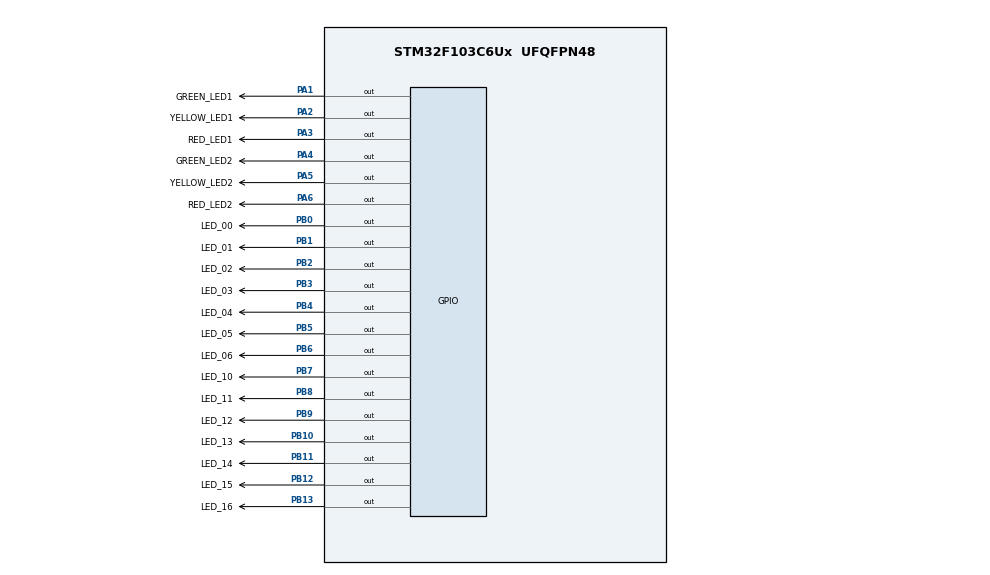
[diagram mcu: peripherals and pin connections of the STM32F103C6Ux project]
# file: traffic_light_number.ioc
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Mcu.Family=STM32F1
Mcu.Name=STM32F103C6Ux
Mcu.Package=UFQFPN48
NVIC.PriorityGroup=NVIC_PRIORITYGROUP_4
NVIC.TIM2_IRQn=true\:0\:0\:false\:false\:true\:true\:true
PA1.GPIO_Label=GREEN_LED1
PA1.Signal=GPIO_Output
PA2.GPIO_Label=YELLOW_LED1
PA2.Signal=GPIO_Output
PA3.GPIO_Label=RED_LED1
PA3.Signal=GPIO_Output
PA4.GPIO_Label=GREEN_LED2
PA4.Signal=GPIO_Output
PA5.GPIO_Label=YELLOW_LED2
PA5.Signal=GPIO_Output
PA6.GPIO_Label=RED_LED2
PA6.Signal=GPIO_Output
PB0.GPIO_Label=LED_00
PB0.Signal=GPIO_Output
PB1.GPIO_Label=LED_01
PB1.Signal=GPIO_Output
PB10.GPIO_Label=LED_13
PB10.Signal=GPIO_Output
PB11.GPIO_Label=LED_14
PB11.Signal=GPIO_Output
PB12.GPIO_Label=LED_15
PB12.Signal=GPIO_Output
PB13.GPIO_Label=LED_16
PB13.Signal=GPIO_Output
PB2.GPIO_Label=LED_02
PB2.Signal=GPIO_Output
PB3.GPIO_Label=LED_03
PB3.Signal=GPIO_Output
PB4.GPIO_Label=LED_04
PB4.Signal=GPIO_Output
PB5.GPIO_Label=LED_05
PB5.Signal=GPIO_Output
PB6.GPIO_Label=LED_06
PB6.Signal=GPIO_Output
PB7.GPIO_Label=LED_10
PB7.Signal=GPIO_Output
PB8.GPIO_Label=LED_11
PB8.Signal=GPIO_Output
PB9.GPIO_Label=LED_12
PB9.Signal=GPIO_Output
ProjectManager.HeapSize=0x200
ProjectManager.StackSize=0x400
ProjectManager.TargetToolchain=STM32CubeIDE
RCC.APB1Freq_Value=8000000
RCC.APB2Freq_Value=8000000
TIM2.Period=9
TIM2.Prescaler=7999
VP_SYS_VS_ND.Mode=No_Debug
VP_TIM2_VS_ClockSourceINT.Mode=Internal
board=custom

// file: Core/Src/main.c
/* USER CODE BEGIN Header */
/**
  ******************************************************************************
  * @file           : main.c
  * @brief          : Main program body
  ******************************************************************************
  * @attention
  *
  * <h2><center>&copy; Copyright (c) 2024 STMicroelectronics.
  * All rights reserved.</center></h2>
  *
  * This software component is licensed by ST under BSD 3-Clause license,
  * the "License"; You may not use this file except in compliance with the
  * License. You may obtain a copy of the License at:
  *                        opensource.org/licenses/BSD-3-Clause
  *
  ******************************************************************************
  */
/* USER CODE END Header */
#include "main.h"
#include "software_timer.h"

TIM_HandleTypeDef htim2;

void SystemClock_Config(void);
static void MX_GPIO_Init(void);
static void MX_TIM2_Init(void);

void display7SEG_1(int num){
	  switch(num){
	  case 0 :
		  HAL_GPIO_WritePin ( LED_10_GPIO_Port , LED_10_Pin , GPIO_PIN_RESET ) ;
		  HAL_GPIO_WritePin ( LED_11_GPIO_Port , LED_11_Pin , GPIO_PIN_RESET ) ;
		  HAL_GPIO_WritePin ( LED_12_GPIO_Port , LED_12_Pin , GPIO_PIN_RESET ) ;
		  HAL_GPIO_WritePin ( LED_13_GPIO_Port , LED_13_Pin , GPIO_PIN_RESET ) ;
		  HAL_GPIO_WritePin ( LED_14_GPIO_Port , LED_14_Pin , GPIO_PIN_RESET ) ;
		  HAL_GPIO_WritePin ( LED_15_GPIO_Port , LED_15_Pin , GPIO_PIN_RESET ) ;
		  HAL_GPIO_WritePin ( LED_16_GPIO_Port , LED_16_Pin , GPIO_PIN_SET ) ;
		  break;
	  case 1 :
		  HAL_GPIO_WritePin ( LED_10_GPIO_Port , LED_10_Pin , GPIO_PIN_SET ) ;
		  HAL_GPIO_WritePin ( LED_11_GPIO_Port , LED_11_Pin , GPIO_PIN_RESET ) ;
		  HAL_GPIO_WritePin ( LED_12_GPIO_Port , LED_12_Pin , GPIO_PIN_RESET ) ;
		  HAL_GPIO_WritePin ( LED_13_GPIO_Port , LED_13_Pin , GPIO_PIN_SET ) ;
		  HAL_GPIO_WritePin ( LED_14_GPIO_Port , LED_14_Pin , GPIO_PIN_SET ) ;
		  HAL_GPIO_WritePin ( LED_15_GPIO_Port , LED_15_Pin , GPIO_PIN_SET ) ;
		  HAL_GPIO_WritePin ( LED_16_GPIO_Port , LED_16_Pin , GPIO_PIN_SET ) ;
		  break;
	  case 2 :
		  HAL_GPIO_WritePin ( LED_10_GPIO_Port , LED_10_Pin , GPIO_PIN_RESET ) ;
		  HAL_GPIO_WritePin ( LED_11_GPIO_Port , LED_11_Pin , GPIO_PIN_RESET ) ;
		  HAL_GPIO_WritePin ( LED_12_GPIO_Port , LED_12_Pin , GPIO_PIN_SET ) ;
		  HAL_GPIO_WritePin ( LED_13_GPIO_Port , LED_13_Pin , GPIO_PIN_RESET ) ;
		  HAL_GPIO_WritePin ( LED_14_GPIO_Port , LED_14_Pin , GPIO_PIN_RESET ) ;
		  HAL_GPIO_WritePin ( LED_15_GPIO_Port , LED_15_Pin , GPIO_PIN_SET ) ;
		  HAL_GPIO_WritePin ( LED_16_GPIO_Port , LED_16_Pin , GPIO_PIN_RESET ) ;
		  break;
	  case 3 :
		  HAL_GPIO_WritePin ( LED_10_GPIO_Port , LED_10_Pin , GPIO_PIN_RESET ) ;
		  HAL_GPIO_WritePin ( LED_11_GPIO_Port , LED_11_Pin , GPIO_PIN_RESET ) ;
		  HAL_GPIO_WritePin ( LED_12_GPIO_Port , LED_12_Pin , GPIO_PIN_RESET ) ;
		  HAL_GPIO_WritePin ( LED_13_GPIO_Port , LED_13_Pin , GPIO_PIN_RESET ) ;
		  HAL_GPIO_WritePin ( LED_14_GPIO_Port , LED_14_Pin , GPIO_PIN_SET ) ;
		  HAL_GPIO_WritePin ( LED_15_GPIO_Port , LED_15_Pin , GPIO_PIN_SET ) ;
		  HAL_GPIO_WritePin ( LED_16_GPIO_Port , LED_16_Pin , GPIO_PIN_RESET ) ;
		  break;
	  case 4 :
		  HAL_GPIO_WritePin ( LED_10_GPIO_Port , LED_10_Pin , GPIO_PIN_SET ) ;
		  HAL_GPIO_WritePin ( LED_11_GPIO_Port , LED_11_Pin , GPIO_PIN_RESET ) ;
		  HAL_GPIO_WritePin ( LED_12_GPIO_Port , LED_12_Pin , GPIO_PIN_RESET ) ;
		  HAL_GPIO_WritePin ( LED_13_GPIO_Port , LED_13_Pin , GPIO_PIN_SET ) ;
		  HAL_GPIO_WritePin ( LED_14_GPIO_Port , LED_14_Pin , GPIO_PIN_SET ) ;
		  HAL_GPIO_WritePin ( LED_15_GPIO_Port , LED_15_Pin , GPIO_PIN_RESET ) ;
		  HAL_GPIO_WritePin ( LED_16_GPIO_Port , LED_16_Pin , GPIO_PIN_RESET ) ;
		  break;
	  case 5 :
		  HAL_GPIO_WritePin ( LED_10_GPIO_Port , LED_10_Pin , GPIO_PIN_RESET ) ;
		  HAL_GPIO_WritePin ( LED_11_GPIO_Port , LED_11_Pin , GPIO_PIN_SET ) ;
		  HAL_GPIO_WritePin ( LED_12_GPIO_Port , LED_12_Pin , GPIO_PIN_RESET ) ;
		  HAL_GPIO_WritePin ( LED_13_GPIO_Port , LED_13_Pin , GPIO_PIN_RESET ) ;
		  HAL_GPIO_WritePin ( LED_14_GPIO_Port , LED_14_Pin , GPIO_PIN_SET ) ;
		  HAL_GPIO_WritePin ( LED_15_GPIO_Port , LED_15_Pin , GPIO_PIN_RESET ) ;
		  HAL_GPIO_WritePin ( LED_16_GPIO_Port , LED_16_Pin , GPIO_PIN_RESET ) ;
		  break;
	  case 6 :
		  HAL_GPIO_WritePin ( LED_10_GPIO_Port , LED_10_Pin , GPIO_PIN_RESET ) ;
		  HAL_GPIO_WritePin ( LED_11_GPIO_Port , LED_11_Pin , GPIO_PIN_SET ) ;
		  HAL_GPIO_WritePin ( LED_12_GPIO_Port , LED_12_Pin , GPIO_PIN_RESET ) ;
		  HAL_GPIO_WritePin ( LED_13_GPIO_Port , LED_13_Pin , GPIO_PIN_RESET ) ;
		  HAL_GPIO_WritePin ( LED_14_GPIO_Port , LED_14_Pin , GPIO_PIN_RESET ) ;
		  HAL_GPIO_WritePin ( LED_15_GPIO_Port , LED_15_Pin , GPIO_PIN_RESET ) ;
		  HAL_GPIO_WritePin ( LED_16_GPIO_Port , LED_16_Pin , GPIO_PIN_RESET ) ;
		  break;
	  case 7 :
		  HAL_GPIO_WritePin ( LED_10_GPIO_Port , LED_10_Pin , GPIO_PIN_RESET ) ;
		  HAL_GPIO_WritePin ( LED_11_GPIO_Port , LED_11_Pin , GPIO_PIN_RESET ) ;
		  HAL_GPIO_WritePin ( LED_12_GPIO_Port , LED_12_Pin , GPIO_PIN_RESET ) ;
		  HAL_GPIO_WritePin ( LED_13_GPIO_Port , LED_13_Pin , GPIO_PIN_SET ) ;
		  HAL_GPIO_WritePin ( LED_14_GPIO_Port , LED_14_Pin , GPIO_PIN_SET ) ;
		  HAL_GPIO_WritePin ( LED_15_GPIO_Port , LED_15_Pin , GPIO_PIN_SET ) ;
		  HAL_GPIO_WritePin ( LED_16_GPIO_Port , LED_16_Pin , GPIO_PIN_SET ) ;
		  break;

	  case 8 :
		  HAL_GPIO_WritePin ( LED_10_GPIO_Port , LED_10_Pin , GPIO_PIN_RESET ) ;
		  HAL_GPIO_WritePin ( LED_11_GPIO_Port , LED_11_Pin , GPIO_PIN_RESET ) ;
		  HAL_GPIO_WritePin ( LED_12_GPIO_Port , LED_12_Pin , GPIO_PIN_RESET ) ;
		  HAL_GPIO_WritePin ( LED_13_GPIO_Port , LED_13_Pin , GPIO_PIN_RESET ) ;
		  HAL_GPIO_WritePin ( LED_14_GPIO_Port , LED_14_Pin , GPIO_PIN_RESET ) ;
		  HAL_GPIO_WritePin ( LED_15_GPIO_Port , LED_15_Pin , GPIO_PIN_RESET ) ;
		  HAL_GPIO_WritePin ( LED_16_GPIO_Port , LED_16_Pin , GPIO_PIN_RESET ) ;
		  break;

	  case 9 :
		  HAL_GPIO_WritePin ( LED_10_GPIO_Port , LED_10_Pin , GPIO_PIN_RESET ) ;
		  HAL_GPIO_WritePin ( LED_11_GPIO_Port , LED_11_Pin , GPIO_PIN_RESET ) ;
		  HAL_GPIO_WritePin ( LED_12_GPIO_Port , LED_12_Pin , GPIO_PIN_RESET ) ;
		  HAL_GPIO_WritePin ( LED_13_GPIO_Port , LED_13_Pin , GPIO_PIN_RESET ) ;
		  HAL_GPIO_WritePin ( LED_14_GPIO_Port , LED_14_Pin , GPIO_PIN_SET ) ;
		  HAL_GPIO_WritePin ( LED_15_GPIO_Port , LED_15_Pin , GPIO_PIN_RESET ) ;
		  HAL_GPIO_WritePin ( LED_16_GPIO_Port , LED_16_Pin , GPIO_PIN_RESET ) ;
		  break;
	  default :
		  break;
	  }
  }
void display7SEG_0(int num){
	  switch(num){
	  case 0 :
		  HAL_GPIO_WritePin ( LED_00_GPIO_Port , LED_00_Pin , GPIO_PIN_RESET ) ;
		  HAL_GPIO_WritePin ( LED_01_GPIO_Port , LED_01_Pin , GPIO_PIN_RESET ) ;
		  HAL_GPIO_WritePin ( LED_02_GPIO_Port , LED_02_Pin , GPIO_PIN_RESET ) ;
		  HAL_GPIO_WritePin ( LED_03_GPIO_Port , LED_03_Pin , GPIO_PIN_RESET ) ;
		  HAL_GPIO_WritePin ( LED_04_GPIO_Port , LED_04_Pin , GPIO_PIN_RESET ) ;
		  HAL_GPIO_WritePin ( LED_05_GPIO_Port , LED_05_Pin , GPIO_PIN_RESET ) ;
		  HAL_GPIO_WritePin ( LED_06_GPIO_Port , LED_06_Pin , GPIO_PIN_SET ) ;
		  break;
	  case 1 :
		  HAL_GPIO_WritePin ( LED_00_GPIO_Port , LED_00_Pin , GPIO_PIN_SET ) ;
		  HAL_GPIO_WritePin ( LED_01_GPIO_Port , LED_01_Pin , GPIO_PIN_RESET ) ;
		  HAL_GPIO_WritePin ( LED_02_GPIO_Port , LED_02_Pin , GPIO_PIN_RESET ) ;
		  HAL_GPIO_WritePin ( LED_03_GPIO_Port , LED_03_Pin , GPIO_PIN_SET ) ;
		  HAL_GPIO_WritePin ( LED_04_GPIO_Port , LED_04_Pin , GPIO_PIN_SET ) ;
		  HAL_GPIO_WritePin ( LED_05_GPIO_Port , LED_05_Pin , GPIO_PIN_SET ) ;
		  HAL_GPIO_WritePin ( LED_06_GPIO_Port , LED_06_Pin , GPIO_PIN_SET ) ;
		  break;
	  case 2 :
		  HAL_GPIO_WritePin ( LED_00_GPIO_Port , LED_00_Pin , GPIO_PIN_RESET ) ;
		  HAL_GPIO_WritePin ( LED_01_GPIO_Port , LED_01_Pin , GPIO_PIN_RESET ) ;
		  HAL_GPIO_WritePin ( LED_02_GPIO_Port , LED_02_Pin , GPIO_PIN_SET ) ;
		  HAL_GPIO_WritePin ( LED_03_GPIO_Port , LED_03_Pin , GPIO_PIN_RESET ) ;
		  HAL_GPIO_WritePin ( LED_04_GPIO_Port , LED_04_Pin , GPIO_PIN_RESET ) ;
		  HAL_GPIO_WritePin ( LED_05_GPIO_Port , LED_05_Pin , GPIO_PIN_SET ) ;
		  HAL_GPIO_WritePin ( LED_06_GPIO_Port , LED_06_Pin , GPIO_PIN_RESET ) ;
		  break;
	  case 3 :
		  HAL_GPIO_WritePin ( LED_00_GPIO_Port , LED_00_Pin , GPIO_PIN_RESET ) ;
		  HAL_GPIO_WritePin ( LED_01_GPIO_Port , LED_01_Pin , GPIO_PIN_RESET ) ;
		  HAL_GPIO_WritePin ( LED_02_GPIO_Port , LED_02_Pin , GPIO_PIN_RESET ) ;
		  HAL_GPIO_WritePin ( LED_03_GPIO_Port , LED_03_Pin , GPIO_PIN_RESET ) ;
		  HAL_GPIO_WritePin ( LED_04_GPIO_Port , LED_04_Pin , GPIO_PIN_SET ) ;
		  HAL_GPIO_WritePin ( LED_05_GPIO_Port , LED_05_Pin , GPIO_PIN_SET ) ;
		  HAL_GPIO_WritePin ( LED_06_GPIO_Port , LED_06_Pin , GPIO_PIN_RESET ) ;
		  break;
	  case 4 :
		  HAL_GPIO_WritePin ( LED_00_GPIO_Port , LED_00_Pin , GPIO_PIN_SET ) ;
		  HAL_GPIO_WritePin ( LED_01_GPIO_Port , LED_01_Pin , GPIO_PIN_RESET ) ;
		  HAL_GPIO_WritePin ( LED_02_GPIO_Port , LED_02_Pin , GPIO_PIN_RESET ) ;
		  HAL_GPIO_WritePin ( LED_03_GPIO_Port , LED_03_Pin , GPIO_PIN_SET ) ;
		  HAL_GPIO_WritePin ( LED_04_GPIO_Port , LED_04_Pin , GPIO_PIN_SET ) ;
		  HAL_GPIO_WritePin ( LED_05_GPIO_Port , LED_05_Pin , GPIO_PIN_RESET ) ;
		  HAL_GPIO_WritePin ( LED_06_GPIO_Port , LED_06_Pin , GPIO_PIN_RESET ) ;
		  break;
	  case 5 :
		  HAL_GPIO_WritePin ( LED_00_GPIO_Port , LED_00_Pin , GPIO_PIN_RESET ) ;
		  HAL_GPIO_WritePin ( LED_01_GPIO_Port , LED_01_Pin , GPIO_PIN_SET ) ;
		  HAL_GPIO_WritePin ( LED_02_GPIO_Port , LED_02_Pin , GPIO_PIN_RESET ) ;
		  HAL_GPIO_WritePin ( LED_03_GPIO_Port , LED_03_Pin , GPIO_PIN_RESET ) ;
		  HAL_GPIO_WritePin ( LED_04_GPIO_Port , LED_04_Pin , GPIO_PIN_SET ) ;
		  HAL_GPIO_WritePin ( LED_05_GPIO_Port , LED_05_Pin , GPIO_PIN_RESET ) ;
		  HAL_GPIO_WritePin ( LED_06_GPIO_Port , LED_06_Pin , GPIO_PIN_RESET ) ;
		  break;
	  case 6 :
		  HAL_GPIO_WritePin ( LED_00_GPIO_Port , LED_00_Pin , GPIO_PIN_RESET ) ;
		  HAL_GPIO_WritePin ( LED_01_GPIO_Port , LED_01_Pin , GPIO_PIN_SET ) ;
		  HAL_GPIO_WritePin ( LED_02_GPIO_Port , LED_02_Pin , GPIO_PIN_RESET ) ;
		  HAL_GPIO_WritePin ( LED_03_GPIO_Port , LED_03_Pin , GPIO_PIN_RESET ) ;
		  HAL_GPIO_WritePin ( LED_04_GPIO_Port , LED_04_Pin , GPIO_PIN_RESET ) ;
		  HAL_GPIO_WritePin ( LED_05_GPIO_Port , LED_05_Pin , GPIO_PIN_RESET ) ;
		  HAL_GPIO_WritePin ( LED_06_GPIO_Port , LED_06_Pin , GPIO_PIN_RESET ) ;
		  break;
	  case 7 :
		  HAL_GPIO_WritePin ( LED_00_GPIO_Port , LED_00_Pin , GPIO_PIN_RESET ) ;
		  HAL_GPIO_WritePin ( LED_01_GPIO_Port , LED_01_Pin , GPIO_PIN_RESET ) ;
		  HAL_GPIO_WritePin ( LED_02_GPIO_Port , LED_02_Pin , GPIO_PIN_RESET ) ;
		  HAL_GPIO_WritePin ( LED_03_GPIO_Port , LED_03_Pin , GPIO_PIN_SET ) ;
		  HAL_GPIO_WritePin ( LED_04_GPIO_Port , LED_04_Pin , GPIO_PIN_SET ) ;
		  HAL_GPIO_WritePin ( LED_05_GPIO_Port , LED_05_Pin , GPIO_PIN_SET ) ;
		  HAL_GPIO_WritePin ( LED_06_GPIO_Port , LED_06_Pin , GPIO_PIN_SET ) ;
		  break;

	  case 8 :
		  HAL_GPIO_WritePin ( LED_00_GPIO_Port , LED_00_Pin , GPIO_PIN_RESET ) ;
		  HAL_GPIO_WritePin ( LED_01_GPIO_Port , LED_01_Pin , GPIO_PIN_RESET ) ;
		  HAL_GPIO_WritePin ( LED_02_GPIO_Port , LED_02_Pin , GPIO_PIN_RESET ) ;
		  HAL_GPIO_WritePin ( LED_03_GPIO_Port , LED_03_Pin , GPIO_PIN_RESET ) ;
		  HAL_GPIO_WritePin ( LED_04_GPIO_Port , LED_04_Pin , GPIO_PIN_RESET ) ;
		  HAL_GPIO_WritePin ( LED_05_GPIO_Port , LED_05_Pin , GPIO_PIN_RESET ) ;
		  HAL_GPIO_WritePin ( LED_06_GPIO_Port , LED_06_Pin , GPIO_PIN_RESET ) ;
		  break;

	  case 9 :
		  HAL_GPIO_WritePin ( LED_00_GPIO_Port , LED_00_Pin , GPIO_PIN_RESET ) ;
		  HAL_GPIO_WritePin ( LED_01_GPIO_Port , LED_01_Pin , GPIO_PIN_RESET ) ;
		  HAL_GPIO_WritePin ( LED_02_GPIO_Port , LED_02_Pin , GPIO_PIN_RESET ) ;
		  HAL_GPIO_WritePin ( LED_03_GPIO_Port , LED_03_Pin , GPIO_PIN_RESET ) ;
		  HAL_GPIO_WritePin ( LED_04_GPIO_Port , LED_04_Pin , GPIO_PIN_SET ) ;
		  HAL_GPIO_WritePin ( LED_05_GPIO_Port , LED_05_Pin , GPIO_PIN_RESET ) ;
		  HAL_GPIO_WritePin ( LED_06_GPIO_Port , LED_06_Pin , GPIO_PIN_RESET ) ;
		  break;
	  default :
		  break;
	  }
  }
int main(void)
{

  /* MCU Configuration--------------------------------------------------------*/

  /* Reset of all peripherals, Initializes the Flash interface and the Systick. */
  HAL_Init();

  /* Configure the system clock */
  SystemClock_Config();

  /* Initialize all configured peripherals */
  MX_GPIO_Init();
  MX_TIM2_Init();
  /* USER CODE BEGIN 2 */
  HAL_TIM_Base_Start_IT (& htim2 ) ;
  /* USER CODE END 2 */

  /* Infinite loop */
  /* USER CODE BEGIN WHILE */
  setTimer(0,100);
  int counter=0;
  while (1)
  {
    /* USER CODE END WHILE */
	  if(isTimerExpired(0))
		  {setTimer(0,100);
		  counter++;}
	  	if (counter<=5){
	  		display7SEG_0(5-counter);
	  		display7SEG_1(7-counter);
	  		HAL_GPIO_WritePin(GPIOA, GREEN_LED1_Pin|RED_LED2_Pin, GPIO_PIN_SET);
	  		HAL_GPIO_WritePin(GPIOA, YELLOW_LED1_Pin|RED_LED1_Pin|GREEN_LED2_Pin
	                  |YELLOW_LED2_Pin, GPIO_PIN_RESET);
	  	}
	  	if (counter>5 && counter<=7){
	  		display7SEG_0(7-counter);
	  		display7SEG_1(7-counter);
	  		HAL_GPIO_WritePin(GPIOA, YELLOW_LED1_Pin|RED_LED2_Pin, GPIO_PIN_SET);
	  		HAL_GPIO_WritePin(GPIOA, GREEN_LED1_Pin|RED_LED1_Pin|GREEN_LED2_Pin
	                  |YELLOW_LED2_Pin, GPIO_PIN_RESET);
	  	}
	  	if (counter>7 && counter<=12){
	  		display7SEG_0(14-counter);
	  		display7SEG_1(12-counter);
	  		HAL_GPIO_WritePin(GPIOA, RED_LED1_Pin|GREEN_LED2_Pin, GPIO_PIN_SET);
	  		HAL_GPIO_WritePin(GPIOA, GREEN_LED1_Pin|RED_LED2_Pin|YELLOW_LED1_Pin
	                  |YELLOW_LED2_Pin, GPIO_PIN_RESET);
	  	}
	  	if (counter>12 && counter<=14){
	  		display7SEG_0(14-counter);
	  		display7SEG_1(14-counter);
	  		HAL_GPIO_WritePin(GPIOA, RED_LED1_Pin|YELLOW_LED2_Pin, GPIO_PIN_SET);
	  		HAL_GPIO_WritePin(GPIOA, GREEN_LED1_Pin|RED_LED2_Pin|YELLOW_LED1_Pin
	  	             |GREEN_LED2_Pin, GPIO_PIN_RESET);
	  	}
	  	if(counter>=14){
	  		counter=0;
	  	}
  }
}

void SystemClock_Config(void)
{
  RCC_OscInitTypeDef RCC_OscInitStruct = {0};
  RCC_ClkInitTypeDef RCC_ClkInitStruct = {0};

  /** Initializes the RCC Oscillators according to the specified parameters
  * in the RCC_OscInitTypeDef structure.
  */
  RCC_OscInitStruct.OscillatorType = RCC_OSCILLATORTYPE_HSI;
  RCC_OscInitStruct.HSIState = RCC_HSI_ON;
  RCC_OscInitStruct.HSICalibrationValue = RCC_HSICALIBRATION_DEFAULT;
  RCC_OscInitStruct.PLL.PLLState = RCC_PLL_NONE;
  if (HAL_RCC_OscConfig(&RCC_OscInitStruct) != HAL_OK)
  {
    Error_Handler();
  }
  /** Initializes the CPU, AHB and APB buses clocks
  */
  RCC_ClkInitStruct.ClockType = RCC_CLOCKTYPE_HCLK|RCC_CLOCKTYPE_SYSCLK
                              |RCC_CLOCKTYPE_PCLK1|RCC_CLOCKTYPE_PCLK2;
  RCC_ClkInitStruct.SYSCLKSource = RCC_SYSCLKSOURCE_HSI;
  RCC_ClkInitStruct.AHBCLKDivider = RCC_SYSCLK_DIV1;
  RCC_ClkInitStruct.APB1CLKDivider = RCC_HCLK_DIV1;
  RCC_ClkInitStruct.APB2CLKDivider = RCC_HCLK_DIV1;

  if (HAL_RCC_ClockConfig(&RCC_ClkInitStruct, FLASH_LATENCY_0) != HAL_OK)
  {
    Error_Handler();
  }
}

static void MX_TIM2_Init(void)
{

  TIM_ClockConfigTypeDef sClockSourceConfig = {0};
  TIM_MasterConfigTypeDef sMasterConfig = {0};

  htim2.Instance = TIM2;
  htim2.Init.Prescaler = 7999;
  htim2.Init.CounterMode = TIM_COUNTERMODE_UP;
  htim2.Init.Period = 9;
  htim2.Init.ClockDivision = TIM_CLOCKDIVISION_DIV1;
  htim2.Init.AutoReloadPreload = TIM_AUTORELOAD_PRELOAD_DISABLE;
  if (HAL_TIM_Base_Init(&htim2) != HAL_OK)
  {
    Error_Handler();
  }
  sClockSourceConfig.ClockSource = TIM_CLOCKSOURCE_INTERNAL;
  if (HAL_TIM_ConfigClockSource(&htim2, &sClockSourceConfig) != HAL_OK)
  {
    Error_Handler();
  }
  sMasterConfig.MasterOutputTrigger = TIM_TRGO_RESET;
  sMasterConfig.MasterSlaveMode = TIM_MASTERSLAVEMODE_DISABLE;
  if (HAL_TIMEx_MasterConfigSynchronization(&htim2, &sMasterConfig) != HAL_OK)
  {
    Error_Handler();
  }

}

static void MX_GPIO_Init(void)
{
  GPIO_InitTypeDef GPIO_InitStruct = {0};

  /* GPIO Ports Clock Enable */
  __HAL_RCC_GPIOA_CLK_ENABLE();
  __HAL_RCC_GPIOB_CLK_ENABLE();

  /*Configure GPIO pin Output Level */
  HAL_GPIO_WritePin(GPIOA, GREEN_LED1_Pin|YELLOW_LED1_Pin|RED_LED1_Pin|GREEN_LED2_Pin
                          |YELLOW_LED2_Pin|RED_LED2_Pin, GPIO_PIN_RESET);

  /*Configure GPIO pin Output Level */
  HAL_GPIO_WritePin(GPIOB, LED_00_Pin|LED_01_Pin|LED_02_Pin|LED_13_Pin
                          |LED_14_Pin|LED_15_Pin|LED_16_Pin|LED_03_Pin
                          |LED_04_Pin|LED_05_Pin|LED_06_Pin|LED_10_Pin
                          |LED_11_Pin|LED_12_Pin, GPIO_PIN_SET);

  /*Configure GPIO pins : GREEN_LED1_Pin YELLOW_LED1_Pin RED_LED1_Pin GREEN_LED2_Pin
                           YELLOW_LED2_Pin RED_LED2_Pin */
  GPIO_InitStruct.Pin = GREEN_LED1_Pin|YELLOW_LED1_Pin|RED_LED1_Pin|GREEN_LED2_Pin
                          |YELLOW_LED2_Pin|RED_LED2_Pin;
  GPIO_InitStruct.Mode = GPIO_MODE_OUTPUT_PP;
  GPIO_InitStruct.Pull = GPIO_NOPULL;
  GPIO_InitStruct.Speed = GPIO_SPEED_FREQ_LOW;
  HAL_GPIO_Init(GPIOA, &GPIO_InitStruct);

  /*Configure GPIO pins : LED_00_Pin LED_01_Pin LED_02_Pin LED_13_Pin
                           LED_14_Pin LED_15_Pin LED_16_Pin LED_03_Pin
                           LED_04_Pin LED_05_Pin LED_06_Pin LED_10_Pin
                           LED_11_Pin LED_12_Pin */
  GPIO_InitStruct.Pin = LED_00_Pin|LED_01_Pin|LED_02_Pin|LED_13_Pin
                          |LED_14_Pin|LED_15_Pin|LED_16_Pin|LED_03_Pin
                          |LED_04_Pin|LED_05_Pin|LED_06_Pin|LED_10_Pin
                          |LED_11_Pin|LED_12_Pin;
  GPIO_InitStruct.Mode = GPIO_MODE_OUTPUT_PP;
  GPIO_InitStruct.Pull = GPIO_NOPULL;
  GPIO_InitStruct.Speed = GPIO_SPEED_FREQ_LOW;
  HAL_GPIO_Init(GPIOB, &GPIO_InitStruct);

}

/* USER CODE BEGIN 4 */

void HAL_TIM_PeriodElapsedCallback ( TIM_HandleTypeDef * htim )
{
	timerRun();
}
/* USER CODE END 4 */

void Error_Handler(void)
{
  __disable_irq();
  while (1)
  {
  }
}

/************************ (C) COPYRIGHT STMicroelectronics *****END OF FILE****/
